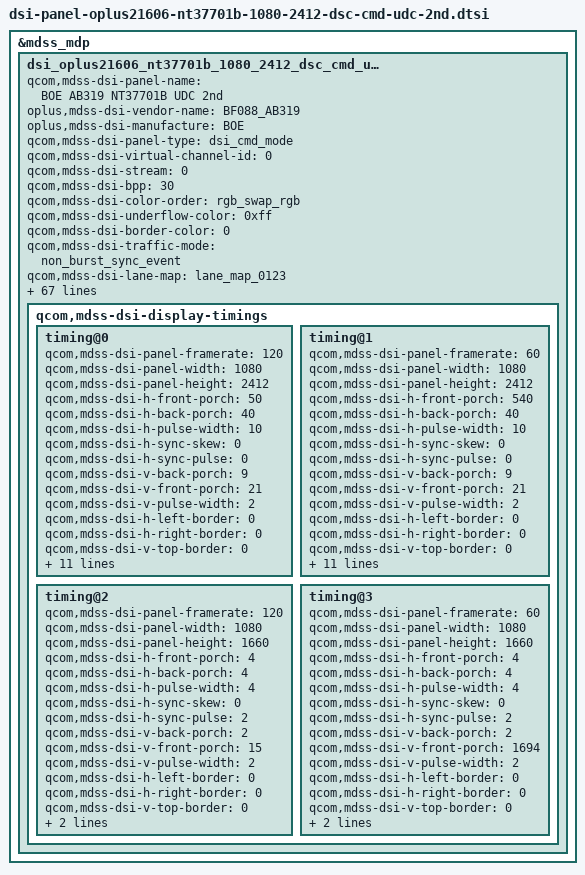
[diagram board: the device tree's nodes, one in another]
&mdss_mdp {
	dsi_oplus21606_nt37701b_1080_2412_dsc_cmd_udc_2nd: qcom,mdss_dsi_oplus21606_nt37701b_1080_2412_dsc_cmd_udc_2nd {
		qcom,mdss-dsi-panel-name = "BOE AB319 NT37701B UDC 2nd";
		oplus,mdss-dsi-vendor-name = "BF088_AB319";
		oplus,mdss-dsi-manufacture = "BOE";
		qcom,mdss-dsi-panel-type = "dsi_cmd_mode";
		qcom,mdss-dsi-virtual-channel-id = <0>;
		qcom,mdss-dsi-stream = <0>;
		qcom,mdss-dsi-bpp = <30>;
		qcom,mdss-dsi-color-order = "rgb_swap_rgb";
		qcom,mdss-dsi-underflow-color = <0xff>;
		qcom,mdss-dsi-border-color = <0>;
		//qcom,dsi-ctrl-num = <0>;
		//qcom,dsi-phy-num = <0>;
		qcom,mdss-dsi-traffic-mode = "non_burst_sync_event";
		qcom,mdss-dsi-lane-map = "lane_map_0123";
		qcom,mdss-dsi-bllp-eof-power-mode;
		qcom,mdss-dsi-bllp-power-mode;
		qcom,mdss-dsi-lane-0-state;
		qcom,mdss-dsi-lane-1-state;
		qcom,mdss-dsi-lane-2-state;
		qcom,mdss-dsi-lane-3-state;
		qcom,mdss-dsi-dma-trigger = "trigger_sw";
		qcom,mdss-dsi-mdp-trigger = "none";
		qcom,mdss-dsi-reset-sequence = <1 10>, <0 10>, <1 10>;

		qcom,mdss-dsi-te-pin-select = <1>;
		qcom,mdss-dsi-te-dcs-command = <1>;
		qcom,mdss-dsi-te-check-enable;
		qcom,mdss-dsi-te-using-te-pin;
		qcom,mdss-dsi-lp11-init;
		qcom,mdss-dsi-wr-mem-start = <0x2c>;
		qcom,mdss-dsi-wr-mem-continue = <0x3c>;
		qcom,mdss-dsi-panel-hdr-enabled;
		qcom,mdss-dsi-panel-hdr-color-primaries = <15635 16450 34000 16000 13250 34500 7500 3000>;
		qcom,mdss-dsi-panel-peak-brightness = <5400000>;
		qcom,mdss-dsi-panel-blackness-level = <2000>;
		qcom,mdss-pan-physical-width-dimension = <70>;
		qcom,mdss-pan-physical-height-dimension = <153>;
		//qcom,esd-check-enabled;
		qcom,mdss-dsi-panel-status-check-mode = "reg_read";
		qcom,mdss-dsi-panel-status-command = [06 01 00 01 05 00 02 0A 00
							06 01 00 01 05 00 02 05 00
							06 01 00 01 05 00 02 03 00
							06 01 00 01 05 00 02 0e 00];
		qcom,mdss-dsi-panel-status-command-state = "dsi_hs_mode";
		qcom,mdss-dsi-panel-status-value = <0x9f 0x00 0x01 0x80>;
		qcom,mdss-dsi-panel-status-read-length = <1 1 1 1>;
		//oplus,esd-err-flag-check-enabled;
		//oplus,esd-err-flag-gpio = <&tlmm 84 0>;
		//oplus,esd-err-trigger-polarity = <1>;
		qcom,dynamic-mode-switch-enabled;
		qcom,dynamic-mode-switch-type = "dynamic-resolution-switch-immediate";
		qcom,mdss-dsi-display-timings {
			timing@0 {
				qcom,mdss-dsi-panel-framerate = <120>;
				//qcom,mdss-dsi-panel-clockrate = <960000000>;
				qcom,mdss-dsi-panel-width = <1080>;
				qcom,mdss-dsi-panel-height = <2412>;
				qcom,mdss-dsi-h-front-porch = <50>;
				qcom,mdss-dsi-h-back-porch = <40>;
				qcom,mdss-dsi-h-pulse-width = <10>;
				qcom,mdss-dsi-h-sync-skew = <0>;
				qcom,mdss-dsi-h-sync-pulse = <0>;
				qcom,mdss-dsi-v-back-porch = <9>;
				qcom,mdss-dsi-v-front-porch = <21>;
				qcom,mdss-dsi-v-pulse-width = <2>;
				qcom,mdss-dsi-h-left-border = <0>;
				qcom,mdss-dsi-h-right-border = <0>;
				qcom,mdss-dsi-v-top-border = <0>;
				qcom,mdss-dsi-v-bottom-border = <0>;
				qcom,mdss-dsi-panel-jitter = <0x4 0x1>;

				oplus,fod-on-vblank = <0>;
				oplus,fod-off-vblank = <3>;

				qcom,compression-mode = "dsc";
				qcom,mdss-dsc-slice-height = <12>;
				qcom,mdss-dsc-slice-width = <540>;
				qcom,mdss-dsc-slice-per-pkt = <2>;
				qcom,mdss-dsc-bit-per-component = <10>;
				qcom,mdss-dsc-bit-per-pixel = <10>;
				qcom,mdss-dsc-block-prediction-enable;
			};

			timing@1 {
				qcom,mdss-dsi-panel-framerate = <60>;
				//qcom,mdss-dsi-panel-clockrate = <960000000>;
				qcom,mdss-dsi-panel-width = <1080>;
				qcom,mdss-dsi-panel-height = <2412>;
				qcom,mdss-dsi-h-front-porch = <540>;
				qcom,mdss-dsi-h-back-porch = <40>;
				qcom,mdss-dsi-h-pulse-width = <10>;
				qcom,mdss-dsi-h-sync-skew = <0>;
				qcom,mdss-dsi-h-sync-pulse = <0>;
				qcom,mdss-dsi-v-back-porch = <9>;
				qcom,mdss-dsi-v-front-porch = <21>;
				qcom,mdss-dsi-v-pulse-width = <2>;
				qcom,mdss-dsi-h-left-border = <0>;
				qcom,mdss-dsi-h-right-border = <0>;
				qcom,mdss-dsi-v-top-border = <0>;
				qcom,mdss-dsi-v-bottom-border = <0>;
				qcom,mdss-dsi-panel-jitter = <0x4 0x1>;

				oplus,fod-on-vblank = <0>;
				oplus,fod-off-vblank = <3>;

				qcom,compression-mode = "dsc";
				qcom,mdss-dsc-slice-height = <12>;
				qcom,mdss-dsc-slice-width = <540>;
				qcom,mdss-dsc-slice-per-pkt = <2>;
				qcom,mdss-dsc-bit-per-component = <10>;
				qcom,mdss-dsc-bit-per-pixel = <10>;
				qcom,mdss-dsc-block-prediction-enable;
			};
			timing@2 {
				qcom,mdss-dsi-panel-framerate = <120>;
				//qcom,mdss-dsi-panel-clockrate = <1320000000>;
				qcom,mdss-dsi-panel-width = <1080>;
				qcom,mdss-dsi-panel-height = <1660>;
				qcom,mdss-dsi-h-front-porch = <4>;
				qcom,mdss-dsi-h-back-porch = <4>;
				qcom,mdss-dsi-h-pulse-width = <4>;
				qcom,mdss-dsi-h-sync-skew = <0>;
				qcom,mdss-dsi-h-sync-pulse = <2>;
				qcom,mdss-dsi-v-back-porch = <2>;
				qcom,mdss-dsi-v-front-porch = <15>;
				qcom,mdss-dsi-v-pulse-width = <2>;
				qcom,mdss-dsi-h-left-border = <0>;
				qcom,mdss-dsi-h-right-border = <0>;
				qcom,mdss-dsi-v-top-border = <0>;
				qcom,mdss-dsi-v-bottom-border = <0>;
				qcom,mdss-dsi-panel-jitter = <0x4 0x1>;
			};
			timing@3 {
				qcom,mdss-dsi-panel-framerate = <60>;
				//qcom,mdss-dsi-panel-clockrate = <1320000000>;
				qcom,mdss-dsi-panel-width = <1080>;
				qcom,mdss-dsi-panel-height = <1660>;
				qcom,mdss-dsi-h-front-porch = <4>;
				qcom,mdss-dsi-h-back-porch = <4>;
				qcom,mdss-dsi-h-pulse-width = <4>;
				qcom,mdss-dsi-h-sync-skew = <0>;
				qcom,mdss-dsi-h-sync-pulse = <2>;
				qcom,mdss-dsi-v-back-porch = <2>;
				qcom,mdss-dsi-v-front-porch = <1694>;
				qcom,mdss-dsi-v-pulse-width = <2>;
				qcom,mdss-dsi-h-left-border = <0>;
				qcom,mdss-dsi-h-right-border = <0>;
				qcom,mdss-dsi-v-top-border = <0>;
				qcom,mdss-dsi-v-bottom-border = <0>;
				qcom,mdss-dsi-panel-jitter = <0x4 0x1>;
			};
		};
	};
};



&dsi_oplus21606_nt37701b_1080_2412_dsc_cmd_udc_2nd {
	//qcom,panel-supply-entries = <&dsi_panel_oplus_jennie_pwr_supply>;
	qcom,mdss-dsi-panel-controller = <&mdss_dsi0>;
	//qcom,mdss-dsi-bl-pmic-control-type = "bl_ctrl_dcs";
	qcom,mdss-dsi-bl-min-level = <1>;
	qcom,mdss-dsi-bl-normal-max-level = <3515>;
	qcom,mdss-dsi-bl-max-level = <4095>;
	qcom,mdss-brightness-normal-max-level = <3515>;
	qcom,mdss-brightness-max-level = <4095>;
	qcom,mdss-brightness-default-level = <400>;
	//qcom,platform-te-gpio = <&tlmm 86 0>;
	//qcom,platform-reset-gpio = <&tlmm 3 0>;
	qcom,platform-panel-vddr-aod-en-gpio = <&tlmm 90 0>;
	qcom,mdss-dsi-reset-sequence = <1 1>, <0 1>, <1 6>;
	//qcom,ulps-enabled;
	//qcom,dsi-dyn-clk-enable;
	//qcom,dsi-dyn-clk-list = <800000000 830000000>;
	//qcom,dsi-select-clocks = "pll_byte_clk0", "pll_dsi_clk0";
	//oplus,osc-support;
	oplus,mdss-dsi-osc-clk-mode0-rate = <180300>;
	oplus,mdss-dsi-osc-clk-mode1-rate = <182300>;
	qcom,mdss-dsi-dc-backlight-level = <1100>;
	oplus,apollo-sync-brightness-level = <711>;
	//oplus,dc_apollo_sync_enable;
	oplus,dc-apollo-backlight-sync-level = <1100>;
	oplus,dc-apollo-backlight-sync-level-pcc-max = <32760>;
	oplus,dc-apollo-backlight-sync-level-pcc-min = <21600>;
	oplus,dsi-fod-brightness = <0 255>,
				<4 238>,
				<256 229>,
				<266 228>,
				<340 220>,
				<430 210>,
				<506 202>,
				<580 194>,
				<710 184>,
				<750 176>,
				<790 171>,
				<852 165>,
				<894 160>,
				<982 152>,
				<1052 146>,
				<1120 139>,
				<1178 133>,
				<1224 128>,
				<1292 121>,
				<1344 116>,
				<1392 111>,
				<1430 106>,
				<1500 99>,
				<1554 94>,
				<1590 89>,
				<1648 83>,
				<1674 80>,
				<1732 74>,
				<1778 69>,
				<1828 64>,
				<1856 61>,
				<1880 58>,
				<1894 56>,
				<1956 50>,
				<2006 44>,
				<2047 40>;

	oplus,dsi-dc-brightness = <0 255>,
			<1 255>,
			<4 248>,
			<8 247>,
			<35 245>,
			<105 243>,
			<195 240>,
			<235 238>,
			<305 233>,
			<400 225>,
			<500 215>,
			<580 205>,
			<591 195>,
			<660 175>,
			<720 155>,
			<780 135>,
			<825 115>,
			<865 95>,
			<900 76>,
			<963 55>,
			<1000 38>,
			<1050 18>,
			<1100 0>;
/*
	oplus,dsi-brightness-remapping = <4    4>,
			<5    5>,
			<6    6>,
			<7    7>,
			<10   10>,
			<244  19>,
			<373  49>,
			<493  90>,
			<585  130>,
			<663  171>,
			<731  212>,
			<792  253>,
			<847  294>,
			<899  335>,
			<948  376>,
			<993  417>,
			<1036 458>,
			<1078 499>,
			<1117 540>,
			<1155 581>,
			<1191 622>,
			<1226 663>,
			<1260 704>,
			<1293 745>,
			<1325 786>,
			<1356 826>,
			<1386 867>,
			<1415 908>,
			<1444 949>,
			<1472 990>,
			<1499 1031>,
			<1526 1072>,
			<1552 1113>,
			<1578 1154>,
			<1603 1195>,
			<1628 1236>,
			<1652 1277>,
			<1676 1318>,
			<1699 1359>,
			<1722 1400>,
			<1745 1441>,
			<1767 1482>,
			<1789 1522>,
			<1811 1563>,
			<1833 1604>,
			<1854 1645>,
			<1875 1686>,
			<1895 1727>,
			<1915 1768>,
			<1935 1809>,
			<1955 1850>,
			<1975 1891>,
			<1994 1932>,
			<2013 1973>,
			<2032 2014>,
			<2043 2038>,
			<2045 2042>,
			<2047 2047>,
			<4095 4095>;
*/
/*	qcom,mdss-dsi-display-timings {
		timing@0 {
				qcom,mdss-dsi-panel-phy-timings = [00 1E 08 07 18 22 08 08 08 02 04 00 1A 0D];
				qcom,display-topology = <1 1 1>,<2 2 1>;
				qcom,default-topology-index = <0>;
		};
		timing@1 {
				qcom,mdss-dsi-panel-phy-timings = [00 1E 08 07 18 22 08 08 08 02 04 00 1A 0D];
				qcom,display-topology = <1 1 1>,<2 2 1>;
				qcom,default-topology-index = <0>;
		};
	};*/
};

